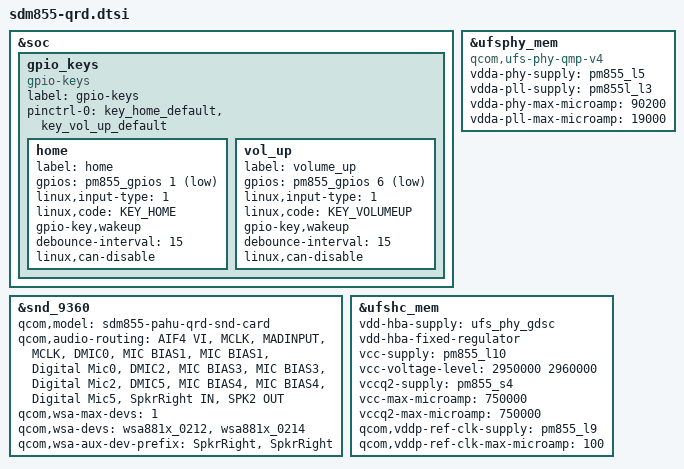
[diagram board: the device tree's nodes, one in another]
/* Copyright (c) 2017-2018, The Linux Foundation. All rights reserved.
 *
 * This program is free software; you can redistribute it and/or modify
 * it under the terms of the GNU General Public License version 2 and
 * only version 2 as published by the Free Software Foundation.
 *
 * This program is distributed in the hope that it will be useful,
 * but WITHOUT ANY WARRANTY; without even the implied warranty of
 * MERCHANTABILITY or FITNESS FOR A PARTICULAR PURPOSE.  See the
 * GNU General Public License for more details.
 */

#include <dt-bindings/gpio/gpio.h>
#include <dt-bindings/input/input.h>

#include "sdm855-pmic-overlay.dtsi"
#include "sdm855-audio-overlay.dtsi"
#include "sdm855-sde-display.dtsi"

&soc {
	gpio_keys {
		compatible = "gpio-keys";
		label = "gpio-keys";

		pinctrl-names = "default";
		pinctrl-0 = <&key_home_default
			     &key_vol_up_default>;

		home {
			label = "home";
			gpios = <&pm855_gpios 1 GPIO_ACTIVE_LOW>;
			linux,input-type = <1>;
			linux,code = <KEY_HOME>;
			gpio-key,wakeup;
			debounce-interval = <15>;
			linux,can-disable;
		};

		vol_up {
			label = "volume_up";
			gpios = <&pm855_gpios 6 GPIO_ACTIVE_LOW>;
			linux,input-type = <1>;
			linux,code = <KEY_VOLUMEUP>;
			gpio-key,wakeup;
			debounce-interval = <15>;
			linux,can-disable;
		};
	};
};

&snd_9360 {
	qcom,model = "sdm855-pahu-qrd-snd-card";
	qcom,audio-routing =
		"AIF4 VI", "MCLK",
		"MADINPUT", "MCLK",
		"DMIC0", "MIC BIAS1",
		"MIC BIAS1", "Digital Mic0",
		"DMIC2", "MIC BIAS3",
		"MIC BIAS3", "Digital Mic2",
		"DMIC5", "MIC BIAS4",
		"MIC BIAS4", "Digital Mic5",
		"SpkrRight IN", "SPK2 OUT";

	qcom,wsa-max-devs = <1>;
	qcom,wsa-devs = <&wsa881x_0212>, <&wsa881x_0214>;
	qcom,wsa-aux-dev-prefix = "SpkrRight", "SpkrRight";
};

&ufsphy_mem {
	compatible = "qcom,ufs-phy-qmp-v4";

	vdda-phy-supply = <&pm855_l5>;
	vdda-pll-supply = <&pm855l_l3>;
	vdda-phy-max-microamp = <90200>;
	vdda-pll-max-microamp = <19000>;

	status = "ok";
};

&ufshc_mem {
	vdd-hba-supply = <&ufs_phy_gdsc>;
	vdd-hba-fixed-regulator;
	vcc-supply = <&pm855_l10>;
	vcc-voltage-level = <2950000 2960000>;
	vccq2-supply = <&pm855_s4>;
	vcc-max-microamp = <750000>;
	vccq2-max-microamp = <750000>;

	qcom,vddp-ref-clk-supply = <&pm855_l9>;
	qcom,vddp-ref-clk-max-microamp = <100>;

	status = "ok";
};
